# MCXN947_cm33_core0 register map
Vendor: nxp.com; File version: 1.0
CPU: CM33 r2p0, little endian, MPU, FPU, VTOR, 3 interrupt priority bits
Registers are 32-bit, read-write, reset 0x0 unless marked. A register's access mark holds for its fields unless they carry their own. Offsets are from the block's base; [hi:lo] are bit positions; lines under a group give offsets from that group; {n}, {i} and the like mark numbered series; 'fields as' and 'values as' point back to an identical list.

## SINC0 — SINC
Base 0x40108000
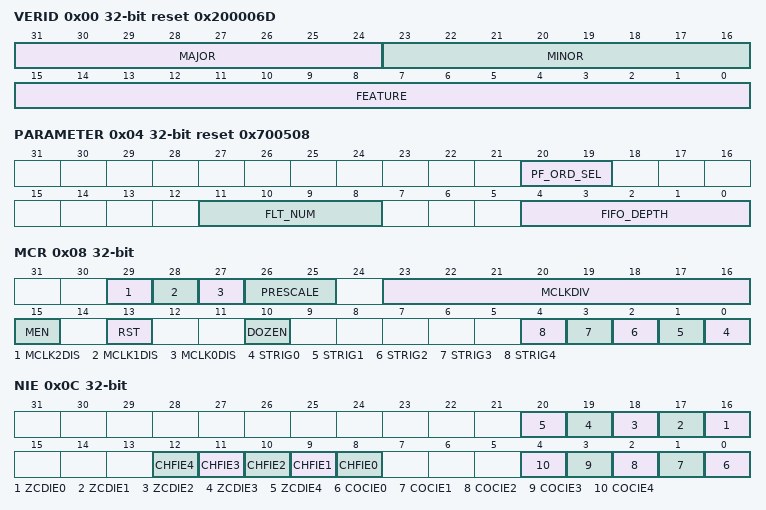
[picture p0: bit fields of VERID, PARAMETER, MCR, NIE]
0x00 VERID ro reset 0x200006D — Version ID
  [31:24] MAJOR — Major Version Number
    1=VER_1 (1.x); 2=VER_2 (2.x)
  [23:16] MINOR — Minor Version Number
    0=VER_2_0 (x.0)
  [15:0] FEATURE — Feature Specification Code
0x04 PARAMETER reset 0x700508 — Parameters
  [20:19] PF_ORD_SEL ro — PF Order Select
    2=ORDER_3 (3); 3=ORDER_2 (2)
  [11:8] FLT_NUM ro — Filter Channel Number
  [4:0] FIFO_DEPTH ro
0x08 MCR — Main Control
  [29] MCLK2DIS — Disable Modulator Clock 2 Output
    0=ENABLED (Enabled when MEN = 1); 1=DISABLED (Disabled regardless of MEN value)
  [28] MCLK1DIS — Disable Modulator Clock 1 Output
    values as MCLK2DIS
  [27] MCLK0DIS — Disable Modulator Clock 0 Output
    values as MCLK2DIS
  [26:25] PRESCALE — Prescale Before Clock Divider
    0=PRESCALE_NO (No prescale); 1=2; 2=4; 3=8
  [23:16] MCLKDIV — Modulator Clock Divider
    0=PROHIBITED
  [15] MEN — Master Enable
    0=DISABLES; 1=ENABLES
  [13] RST — Software Reset
    0=RESET_NO (Do not reset); 1=RESET_YES
  [10] DOZEN — Doze Or Stop Enable
    0=ENABLED (Enables); 1=DISABLED (Disables)
  [n] STRIG{n} (n=0..4) — Software Trigger For Channel {n}
    0=NO_EFFECT; 1=TRIGGER
0x0C NIE — Normal Interrupt Enable
  [all] fields
    0=DISABLES; 1=ENABLES
  [n+16] ZCDIE{n} (n=0..4) — Zero Cross Detected Interrupt Enable
  [n+8] CHFIE{n} (n=0..4) — Data Output Ready Interrupt Enable
  [n] COCIE{n} (n=0..4) — Conversion Complete Interrupt Enable
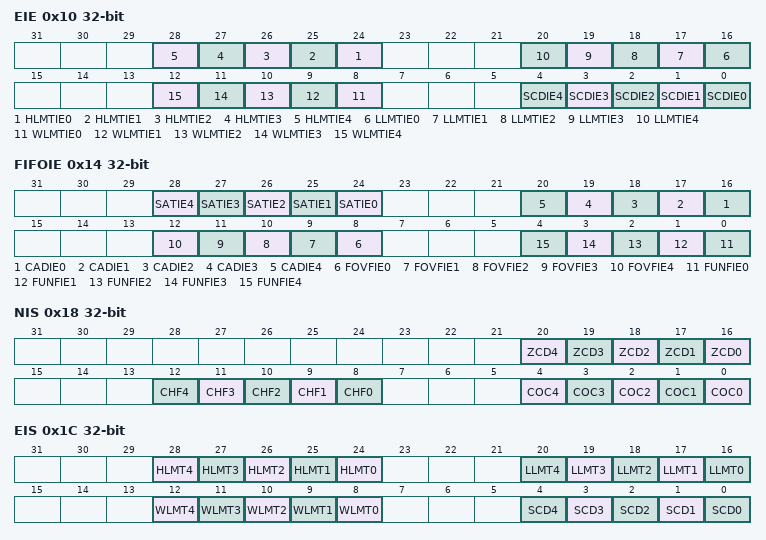
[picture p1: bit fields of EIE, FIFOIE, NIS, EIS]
0x10 EIE — Error Interrupt Enable
  [all] fields
    0=DISABLES; 1=ENABLES
  [n+24] HLMTIE{n} (n=0..4) — High Limit Interrupt Enable
  [n+16] LLMTIE{n} (n=0..4) — Low Limit Interrupt Enable
  [n+8] WLMTIE{n} (n=0..4) — Window Limit Interrupt Enable
  [n] SCDIE{n} (n=0..4) — Short Circuit Detected Interrupt Enable
0x14 FIFOIE — FIFO And CAD Error Interrupt Enable
  [all] fields
    0=DISABLES; 1=ENABLES
  [n+24] SATIE{n} (n=0..4) — Saturation Interrupt Enable
  [n+16] CADIE{n} (n=0..4) — Clock Absence Interrupt Enable
  [n+8] FOVFIE{n} (n=0..4) — FIFO Overflow Interrupt Enable
  [n] FUNFIE{n} (n=0..4) — FIFO Underflow Interrupt Enable
0x18 NIS write-1-clears — Normal Interrupt Status
  [n+16] ZCD{n} write-1-clears (n=0..4) — Zero Cross Detected Flag
    on read: 0=ZC_NO (Not detected); 1=ZC_YES (Detected)
  [n+8] CHF{n} write-1-clears (n=0..4) — Data Output Ready Flag
    on read: 0=OVFLW_NO (No overflow; data not available); 1=OVFLW_YES (Overflow; data available)
  [n] COC{n} write-1-clears (n=0..4) — Conversion Complete Flag
    on read: 0=COC_NO (Not finished; data not available); 1=COC_YES (Finished; data available)
0x1C EIS write-1-clears — Error Interrupt Status
  [n+24] HLMT{n} write-1-clears (n=0..4) — High Limit Flag
    on read: 0=HLMT_NO (Not exceeded); 1=HLMT_YES (Exceeded)
  [n+16] LLMT{n} write-1-clears (n=0..4) — Low Limit Flag
    on read: 0=LLMT_NO (Not exceeded); 1=LLMT_YES (Exceeded)
  [n+8] WLMT{n} write-1-clears (n=0..4) — Window Limit Flag
    on read: 0=WLMT_NO (Not exceeded); 1=WLMT_YES (Exceeded)
  [n] SCD{n} write-1-clears (n=0..4) — Short Circuit Detected Flag
    on read: 0=SC_NO (Not detected); 1=SC_YES (Detected)
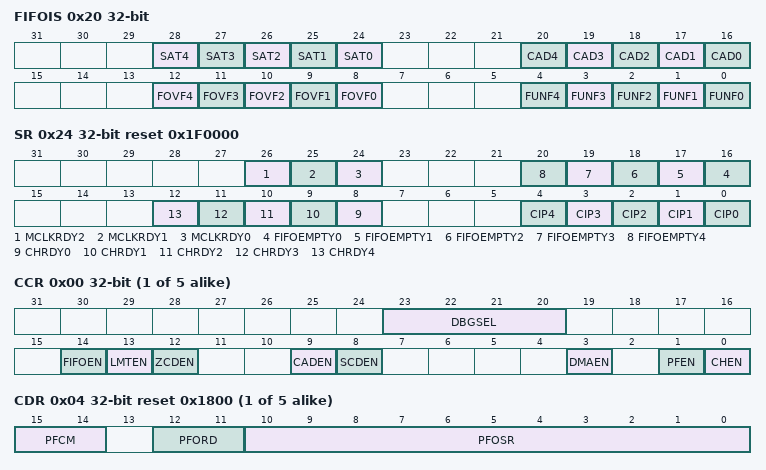
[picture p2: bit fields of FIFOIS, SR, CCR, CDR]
0x20 FIFOIS write-1-clears — FIFO And CAD Error Interrupt Status
  [n+24] SAT{n} write-1-clears (n=0..4) — Saturation Flag
    on read: 0=SAT_NO (Not saturated); 1=SAT_YES (Saturated)
  [n+16] CAD{n} write-1-clears (n=0..4) — Clock Absence Flag
    on read: 0=CAD_NO (Clock present); 1=CAD_YES (Clock absent)
  [n+8] FOVF{n} write-1-clears (n=0..4) — FIFO Overflow Flag
    on read: 0=FOVF_NO (Did not occur); 1=FOVF_YES (Occurred)
  [n] FUNF{n} write-1-clears (n=0..4) — FIFO Underflow Flag
    on read: 0=FUNF_NO (Did not occur); 1=FUNF_YES (Occurred)
0x24 SR ro reset 0x1F0000 — Status
  [26] MCLKRDY2 — Modulator Clock 2 Ready
    0=READY_NO (Not ready); 1=READY_YES
  [25] MCLKRDY1 — Modulator Clock 1 Ready
    0=READY_NO (Not ready); 1=READY_YES
  [24] MCLKRDY0 — Modulator Clock 0 Ready
    0=READY_NO (Not ready); 1=READY_YES
  [n+16] FIFOEMPTY{n} (n=0..4) — FIFO Empty
    0=EMPTY_NO (Not empty); 1=EMPTY_YES
  [n+8] CHRDY{n} (n=0..4) — Channel Ready For Conversion
    0=READY_NO (Not ready); 1=READY_YES
  [n] CIP{n} (n=0..4) — Conversion In Progress
    0=CONV_NO (Not in progress); 1=CONV_YES (In progress)
{0x38+0x30*i} CHANNEL[{i}] (i=0..4) group — Prefetch configuration array
  0x00 CCR — Channel n Control
    [23:20] DBGSEL — Debug Output Selection
      0=RSLT (Final data from the PF (24 bits)); 1=PFBIS (Offset data (24 bits)); 2=PFSFT (Shifted data from the PF (24 bits)); 3=HPF (DC remover (HPF) data (32 bits)); 4=PFCIC (Raw data from the PF's CIC filter); 6=SCD (Historical data from SCD); 7=MM (Data from the Manchester decoder); 8=CAD (Data from CAD); 9=FIFO (Number of available entries in the FIFO); 10=PS (Status of the parallel or serial data converter)
    [14] FIFOEN — FIFO Enable
      0=DISABLES; 1=ENABLES
    [13] LMTEN — Limit Enable
      0=DISABLES; 1=ENABLES
    [12] ZCDEN — Zero Cross Detect Enable
      0=DISABLES; 1=ENABLES
    [9] CADEN — Clock Absence Detect Enable
      0=DISABLES; 1=ENABLES
    [8] SCDEN — Short Circuit Detect Enable
      0=DISABLES; 1=ENABLES
    [3] DMAEN — DMA Enable
      0=DISABLES; 1=ENABLES
    [1] PFEN — PF Enable
      0=DISABLES; 1=ENABLES
    [0] CHEN — Channel Enable
      0=DISABLES; 1=ENABLES
  0x04 CDR reset 0x1800 — Channel n Data Rate
    [15:14] PFCM — PF Conversion Mode
      0=SINGLE; 1=CONTINUOUS; 2=ALWAYS; 3=FIX (Fixed number)
    [12:11] PFORD — PF Order
      0=FASTSINC; 1=ORDER_1 (First order); 2=ORDER_2 (Second order); 3=ORDER_3 (Third order)
    [10:0] PFOSR
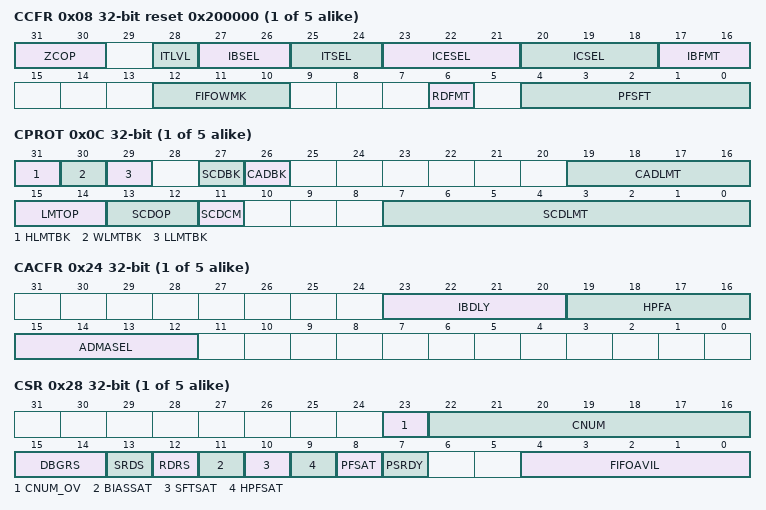
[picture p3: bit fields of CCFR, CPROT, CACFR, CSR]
  0x08 CCFR reset 0x200000 — Channel n Configuration
    [31:30] ZCOP — Zero Cross Option
      0=BOTH (Both rise and fall); 1=FALL; 2=RISE
    [28] ITLVL — Input Trigger Level Type
      0=EDGE; 1=LEVEL
    [27:26] IBSEL — Input Bit Select
      0=EPB (External bitstream from the MBIT[n] signal); 1=ESB (Alternate internal bitstream from the INP[n] signal); 3=GRP (Grouped bitstream shared with an adjacent channel; the adjacent channel's IBSEL field determines the input)
    [25:24] ITSEL — Input Trigger Select
      0=SW (Software); 1=HW (Hardware trigger dedicated to the channel); 3=GP (Grouped trigger shared with an adjacent channel; the adjacent channel's ITSEL field determines the trigger)
    [23:21] ICESEL — Input Clock Edge Select
      1=POS (Positive edge); 2=NEG (Negative edge); 3=BOTH (Both edges); 4=OPOS (Every other odd positive edge); 5=EPOS (Every other even positive edge); 6=ONEG (Every other odd negative edge); 7=ENEG (Every other even negative edge)
    [20:18] ICSEL — Input Clock Select
      0=MCLK_OUT0 (MCLK_OUT0 with internal routeback); 1=MCLK_OUT1 (MCLK_OUT1 with internal routeback); 2=MCLK_OUT2 (MCLK_OUT2 with internal routeback); 3=EXT (External modulator clock dedicated to this channel); 7=GRP (Grouped clock shared with an adjacent channel; the adjacent channel's ICSEL field determines the input clock)
    [17:16] IBFMT — Input Bit Format
      0=E1B (External bitstream from the MBIT[n] signal); 1=EMB (External Manchester code; ICESEL selects the rise or fall decoder); 2=IPB (Internal 16-bit parallel data from MPDATA); 3=ISB (Internal 32-bit serial data from MPDATA)
    [12:10] FIFOWMK — FIFO Watermark
    [6] RDFMT — Result Data Format
      0=SIGNED (Left justified, signed); 1=UNSIGNED (Left justified, unsigned)
    [4:0] PFSFT — PF Shift
  0x0C CPROT — Channel n Protection
    [31] HLMTBK — High Limit Break Signal
      0=DISABLES; 1=ENABLES
    [30] WLMTBK — Window Limit Break Signal
      0=DISABLES; 1=ENABLES
    [29] LLMTBK — Low Limit Break Signal
      0=DISABLES; 1=ENABLES
    [27] SCDBK — SCD Break Signal
      0=DISABLES; 1=ENABLES
    [26] CADBK — CAD Break Signal
      0=DISABLES; 1=ENABLES
    [19:16] CADLMT — CAD Limit Threshold
      0=DISABLES (Disables CAD)
    [15:14] LMTOP — Limit Detection Option
      0=BOTH (Both high and low limits); 1=HIGH (High limit); 2=LOW (Low limit); 3=WINDOW (Windowed value)
    [13:12] SCDOP — SCD Option
      0=BOTH (Both 0 and 1); 1=ONE (Only 1); 2=ZERO (Only 0)
    [11] SCDCM — SCD Conversion Mode
      0=ALWAYS (Constantly when CnCR[CHEN] = MCR[MEN] = 1); 1=DURING_CONV (Only when the PF is performing a conversion)
    [7:0] SCDLMT — SCD Limit Threshold
      0=DISABLES_0 (Disables SCD); 1=DISABLES_1 (Disables SCD)
  0x10 CBIAS — Channel n Bias
    [31:8] BIAS — Bias Value
  0x14 CLOLMT — Channel n Low Limit
    [31:8] LOLMT — Low Limit Threshold
  0x18 CHILMT — Channel n High Limit
    [31:8] HILMT — High Limit Threshold
  0x1C CRDATA ro — Channel n Result Data
    [31:8] RDATA — Result Data
  0x20 CMPDATA — Channel n Multipurpose Data
    [31:0] MPDATA — Multipurpose Data
  0x24 CACFR — Channel n Advanced Configuration
    [23:20] IBDLY — Input Modulator Bitstream Delay
      0=DISABLED
    [19:16] HPFA — HPF DC Remover Alpha Coefficient
    [15:12] ADMASEL — Alternate DMA Source Selection
      0=DISABLED (Alternate DMA disabled); 1=PF_CONV_COMPLETE (PF conversion complete); 2=PF_DATA_READY (PF data output ready); 3=ZCD (Zero crossing detected); 4=SCD (Short circuit detected); 5=WINDOW_LMT (Window limit detected); 6=LOW_LMT (Low limit detected); 7=HIGH_LMT (High limit); 8=FIFO_UF (FIFO underflow); 9=FIFO_OF (FIFO overflow); 10=CLK_ABS (Clock absence); 11=SAT (Saturation)
  0x28 CSR — Channel n Status
    [23] CNUM_OV ro — Overflow In Number Of Conversions
      0=OFLW_NO (No overflow); 1=OFLW_YES (Overflow)
    [22:16] CNUM ro — Number Of Conversions
    [15:14] DBGRS ro — Debug Data Read Status
      0=VALID; 1=INVALID_1; 2=INVALID_2; 3=INVALID_3
    [13] SRDS — Start Read Debug Data Sync
      on read: 0=DATA_VALID; 1=IN_PROGRESS (Procedure in progress)
    [12] RDRS ro — Result Data Direct Read Status
      0=VALID; 1=INVALID
    [11] BIASSAT ro — Bias Saturation Flag
      0=SAT_NO (Did not occur); 1=SAT_YES (Occurred)
    [10] SFTSAT ro — Shift Saturation Flag
      0=SAT_NO (Did not occur); 1=SAT_YES (Occurred)
    [9] HPFSAT ro — HPF Saturation Flag
      0=SAT_NO (Did not occur); 1=SAT_YES (Occurred)
    [8] PFSAT ro — Primary CIC Saturation Flag
      0=SAT_NO (Did not occur); 1=SAT_YES (Occurred)
    [7] PSRDY ro — Parallel or Serial Data Ready
      0=READY_NO (Not ready); 1=READY_YES
    [4:0] FIFOAVIL ro — FIFO Available Data
  0x2C CDBGR ro — Channel n Debug
    [31:0] DBGDATA — Debug Data
